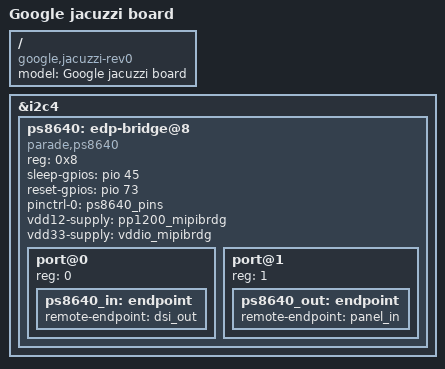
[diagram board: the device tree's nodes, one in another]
// SPDX-License-Identifier: (GPL-2.0 OR MIT)
/*
 * Copyright 2019 Google LLC
 */

/dts-v1/;
#include "mt8183-kukui-jacuzzi.dtsi"
#include "mt8183-kukui-audio-ts3a227e.dtsi"

/ {
	model = "Google jacuzzi board";
	compatible = "google,jacuzzi-rev0", "google,jacuzzi", "mediatek,mt8183";
};

&i2c4 {
	/delete-node/ anx7625@58;

	ps8640: edp-bridge@8 {
		compatible = "parade,ps8640";
		reg = <0x8>;
		sleep-gpios = <&pio 45 GPIO_ACTIVE_HIGH>;
		reset-gpios = <&pio 73 GPIO_ACTIVE_HIGH>;
		pinctrl-names = "default";
		pinctrl-0 = <&ps8640_pins>;
		vdd12-supply = <&pp1200_mipibrdg>;
		vdd33-supply = <&vddio_mipibrdg>;
		#address-cells = <1>;
		#size-cells = <0>;

		port@0 {
			reg = <0>;

			ps8640_in: endpoint {
				remote-endpoint = <&dsi_out>;
			};
		};

		port@1 {
			reg = <1>;

			ps8640_out: endpoint {
				remote-endpoint = <&panel_in>;
			};
		};
	};
};
